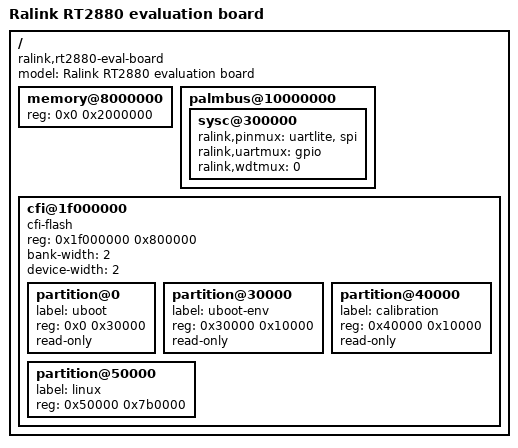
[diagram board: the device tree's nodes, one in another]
/dts-v1/;

/include/ "rt2880.dtsi"

/ {
	#address-cells = <1>;
	#size-cells = <1>;
	compatible = "ralink,rt2880-eval-board", "ralink,rt2880-soc";
	model = "Ralink RT2880 evaluation board";

	memory@8000000 {
		reg = <0x0 0x2000000>;
	};

	palmbus@10000000 {
		sysc@300000 {
			ralink,pinmux = "uartlite", "spi";
			ralink,uartmux = "gpio";
			ralink,wdtmux = <0>;
		};
	};

	cfi@1f000000 {
		compatible = "cfi-flash";
		reg = <0x1f000000 0x800000>;

		bank-width = <2>;
		device-width = <2>;
		#address-cells = <1>;
		#size-cells = <1>;

		partition@0 {
			label = "uboot";
			reg = <0x0 0x30000>;
			read-only;
		};
		partition@30000 {
			label = "uboot-env";
			reg = <0x30000 0x10000>;
			read-only;
		};
		partition@40000 {
			label = "calibration";
			reg = <0x40000 0x10000>;
			read-only;
		};
		partition@50000 {
			label = "linux";
			reg = <0x50000 0x7b0000>;
		};
	};
};
